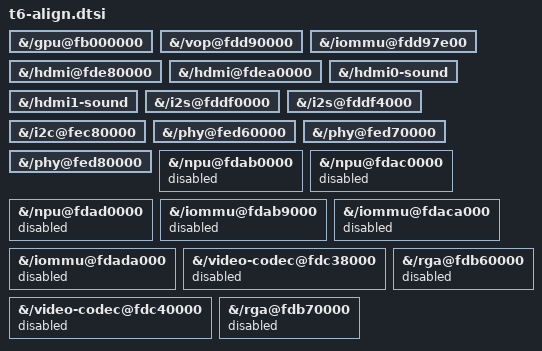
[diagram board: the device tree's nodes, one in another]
/* 自动对齐官方 T6 DTB（refs/t6-official.dtb）：T6 开着、我们关着的一律打开。
 * 板级专属（pcie/网口/存储/LED/PMIC）不在此列，走各自板级配置。
 * NPU 官方 T6 是 disabled，本板保持启用（fnOS 带 rknpu 模块，另行验证）。
 */

/* Mali GPU（不开则 vdd_gpu_s0 断电、DRM 无 VOP、无 /dev/dri） */
&{/gpu@fb000000} {
	status = "okay";
};

/* VOP 显示控制器 */
&{/vop@fdd90000} {
	status = "okay";
};

/* VOP MMU（vop_mmu） */
&{/iommu@fdd97e00} {
	status = "okay";
};

/* HDMI0 */
&{/hdmi@fde80000} {
	status = "okay";
};

/* HDMI1 */
&{/hdmi@fdea0000} {
	status = "okay";
};

/* HDMI0 音频 */
&{/hdmi0-sound} {
	status = "okay";
};

/* HDMI1 音频 */
&{/hdmi1-sound} {
	status = "okay";
};

/* I2S（HDMI 音频通路） */
&{/i2s@fddf0000} {
	status = "okay";
};

/* I2S（HDMI 音频通路） */
&{/i2s@fddf4000} {
	status = "okay";
};

/* HDMI DDC i2c */
&{/i2c@fec80000} {
	status = "okay";
};

/* hdptxphy_hdmi0 */
&{/phy@fed60000} {
	status = "okay";
};

/* hdptxphy_hdmi1 */
&{/phy@fed70000} {
	status = "okay";
};

/* mipi DC-PHY */
&{/phy@fed80000} {
	status = "okay";
};

/* ---- 与 T6 逐节点对齐的“关闭”项 ----
 * T6 官方 DTB：NPU 三个核及其 iommu 全部 disabled；只有 rga@fdb80000、没有
 * fdc38000/fdc40000 这两个 vdec 核。本板为求与官方一致，同样关掉。
 * 注：这些关闭不损失实际功能——官方内核里 rknpu/rga3 的 of_match 都不认 rk3588 节点，
 * 本来也探测不到；关掉只是让 DT 与官方逐节点相同。
 */
&{/npu@fdab0000} { status = "disabled"; };
&{/npu@fdac0000} { status = "disabled"; };
&{/npu@fdad0000} { status = "disabled"; };
&{/iommu@fdab9000} { status = "disabled"; };
&{/iommu@fdaca000} { status = "disabled"; };
&{/iommu@fdada000} { status = "disabled"; };
&{/video-codec@fdc38000} { status = "disabled"; };
&{/video-codec@fdc40000} { status = "disabled"; };
&{/rga@fdb60000} { status = "disabled"; };
&{/rga@fdb70000} { status = "disabled"; };
